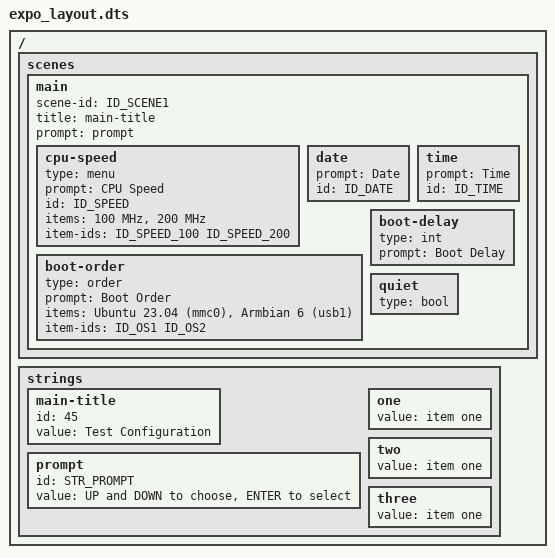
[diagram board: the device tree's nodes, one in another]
// SPDX-License-Identifier: GPL-2.0+
/*
 * Sample expo screen layout
 */

/dts-v1/;

#include "expo_ids.h"

/ {
	scenes {
		main {
			scene-id = <ID_SCENE1>;
			title = "main-title";
			prompt = "prompt";

			cpu-speed {
				type = "menu";
				prompt = "CPU Speed";
				id = <ID_SPEED>;
				items = "100 MHz", "200 MHz";
				item-ids = <ID_SPEED_100 ID_SPEED_200>;
			};

			date {
				prompt = "Date";
				id = <ID_DATE>;
			};

			time {
				prompt = "Time";
				id = <ID_TIME>;
			};

			boot-order {
				type = "order";
				prompt = "Boot Order";
				items = "Ubuntu 23.04 (mmc0)",
					"Armbian 6 (usb1)";
				item-ids = <ID_OS1 ID_OS2>;
			};

			boot-delay {
				type = "int";
				prompt = "Boot Delay";
			};

			quiet {
				type = "bool";
			};
		};
	};

	strings {
		main-title {
			id = <45>;
			value = "Test Configuration";
		};

		prompt {
			id = <STR_PROMPT>;
			value = "UP and DOWN to choose, ENTER to select";
		};

		one {
			value = "item one";
		};

		two {
			value = "item one";
		};

		three {
			value = "item one";
		};
	};
};
